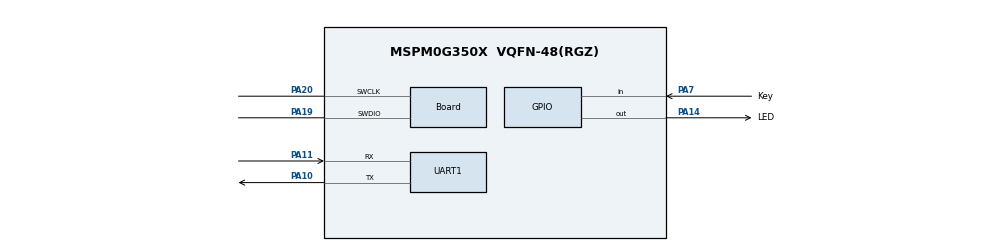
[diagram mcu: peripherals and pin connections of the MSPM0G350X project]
/**
 * @cliArgs --device "MSPM0G350X" --package "VQFN-48(RGZ)" --part "Default" --product "mspm0_sdk@1.20.01.06"
 * @versions {"tool":"1.18.1+3343"}
 */

/**
 * Import the modules used in this configuration.
 */
const ADC12         = scripting.addModule("/ti/driverlib/ADC12", {}, false);
const ADC121        = ADC12.addInstance();
const Board         = scripting.addModule("/ti/driverlib/Board");
const GPIO          = scripting.addModule("/ti/driverlib/GPIO", {}, false);
const GPIO1         = GPIO.addInstance();
const SYSCTL        = scripting.addModule("/ti/driverlib/SYSCTL");
const UART          = scripting.addModule("/ti/driverlib/UART", {}, false);
const UART1         = UART.addInstance();
const ProjectConfig = scripting.addModule("/ti/project_config/ProjectConfig");

/**
 * Write custom configuration values to the imported modules.
 */
const gate7  = system.clockTree["MFCLKGATE"];
gate7.enable = true;

const gate8  = system.clockTree["MFPCLKGATE"];
gate8.enable = true;

ADC121.sampClkSrc                        = "DL_ADC12_CLOCK_ULPCLK";
ADC121.enabledInterrupts                 = ["DL_ADC12_INTERRUPT_MEM0_RESULT_LOADED"];
ADC121.sampleTime0                       = "125us";
ADC121.$name                             = "ADC12_0";
ADC121.peripheral.$assign                = "ADC0";
ADC121.adcPin0Config.$name               = "ti_driverlib_gpio_GPIOPinGeneric0";
ADC121.adcPin0Config.hideOutputInversion = scripting.forceWrite(false);

Board.peripheral.$assign          = "DEBUGSS";
Board.peripheral.swclkPin.$assign = "PA20";
Board.peripheral.swdioPin.$assign = "PA19";

GPIO1.$name                              = "Demo";
GPIO1.associatedPins.create(2);
GPIO1.associatedPins[0].$name            = "LED";
GPIO1.associatedPins[0].assignedPort     = "PORTA";
GPIO1.associatedPins[0].assignedPin      = "14";
GPIO1.associatedPins[0].subOutputPolicy  = "TOGGLE";
GPIO1.associatedPins[0].subChanID        = 1;
GPIO1.associatedPins[0].pin.$assign      = "PA14";
GPIO1.associatedPins[1].$name            = "Key";
GPIO1.associatedPins[1].assignedPort     = "PORTA";
GPIO1.associatedPins[1].assignedPin      = "7";
GPIO1.associatedPins[1].internalResistor = "PULL_UP";
GPIO1.associatedPins[1].direction        = "INPUT";
GPIO1.associatedPins[1].interruptEn      = true;
GPIO1.associatedPins[1].polarity         = "RISE_FALL";
GPIO1.associatedPins[1].pubChanID        = 1;
GPIO1.associatedPins[1].pin.$assign      = "PA7";

SYSCTL.MFCLKEn     = true;
SYSCTL.MFPCLKEn    = true;
SYSCTL.clockTreeEn = true;

UART1.$name                    = "UART_0";
UART1.uartClkSrc               = "MFCLK";
UART1.targetBaudRate           = 115200;
UART1.enabledInterrupts        = ["RX"];
UART1.peripheral.$assign       = "UART0";
UART1.peripheral.rxPin.$assign = "PA11";
UART1.peripheral.txPin.$assign = "PA10";
UART1.txPinConfig.$name        = "ti_driverlib_gpio_GPIOPinGeneric1";
UART1.rxPinConfig.$name        = "ti_driverlib_gpio_GPIOPinGeneric2";

ProjectConfig.deviceSpin = "MSPM0G3507";

/**
 * Pinmux solution for unlocked pins/peripherals. This ensures that minor changes to the automatic solver in a future
 * version of the tool will not impact the pinmux you originally saw.  These lines can be completely deleted in order to
 * re-solve from scratch.
 */
ADC121.peripheral.adcPin0.$suggestSolution = "PA27";
